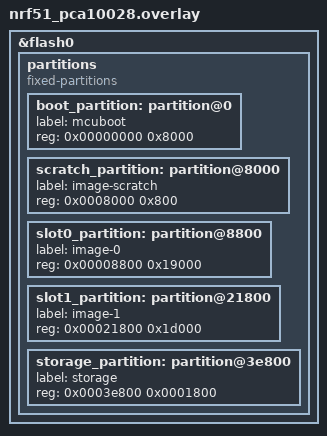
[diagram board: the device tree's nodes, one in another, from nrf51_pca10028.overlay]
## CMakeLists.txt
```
# SPDX-License-Identifier: Apache-2.0

cmake_minimum_required(VERSION 3.13.1)
include($ENV{ZEPHYR_BASE}/cmake/app/boilerplate.cmake NO_POLICY_SCOPE)
project(test_zepboot)

FILE(GLOB app_sources ../zepboot/src/*.c src/*.c)

target_sources(app PRIVATE ${app_sources})
```

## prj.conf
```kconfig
CONFIG_ZTEST=y
CONFIG_ZTEST_STACKSIZE=8120
CONFIG_MAIN_STACK_SIZE=4096
CONFIG_FLASH=y
CONFIG_FLASH_PAGE_LAYOUT=y
CONFIG_FLASH_MAP=y

CONFIG_TINYCRYPT=y
CONFIG_TINYCRYPT_SHA256=y
CONFIG_TINYCRYPT_ECC_DH=y
CONFIG_TINYCRYPT_ECC_DSA=y
CONFIG_TINYCRYPT_AES=y
CONFIG_TINYCRYPT_AES_CTR=y

CONFIG_LOG=y
CONFIG_LOG_IMMEDIATE=y
```

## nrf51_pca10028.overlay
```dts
/*
 * Copyright (c) 2019 Laczen
 *
 * SPDX-License-Identifier: Apache-2.0
 */

/delete-node/ &storage_partition;
/delete-node/ &slot0_partition;
/delete-node/ &slot1_partition;
/delete-node/ &scratch_partition;
/delete-node/ &boot_partition;

&flash0 {
	/*
	 * For more information, see:
	 * http://docs.zephyrproject.org/latest/guides/dts/index.html#flash-partitions
	 */
	partitions {
		compatible = "fixed-partitions";
		#address-cells = <1>;
		#size-cells = <1>;

		boot_partition: partition@0 {
			label = "mcuboot";
			reg = <0x00000000 0x8000>;
		};
		scratch_partition: partition@8000 {
			label = "image-scratch";
			reg = <0x0008000 0x800>;
		};
		slot0_partition: partition@8800 {
			label = "image-0";
			reg = <0x00008800 0x19000>;
		};
		slot1_partition: partition@21800 {
			label = "image-1";
			reg = <0x00021800 0x1d000>;
		};

		storage_partition: partition@3e800 {
			label = "storage";
			reg = <0x0003e800 0x0001800>;
		};
	};
};
```

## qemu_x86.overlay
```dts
/*
 * Copyright (c) 2019 Laczen
 *
 * SPDX-License-Identifier: Apache-2.0
 */

/delete-node/ &storage_partition;
/delete-node/ &slot0_partition;
/delete-node/ &slot1_partition;

&flash_sim0 {
	/*
	 * For more information, see:
	 * http://docs.zephyrproject.org/latest/guides/dts/index.html#flash-partitions
	 */
	partitions {
		compatible = "fixed-partitions";
		#address-cells = <1>;
		#size-cells = <1>;

		storage_partition: partition@1000 {
			label = "storage";
			reg = <0x00001000 0x00010000>;
		};

		slot0_partition: partition@11000 {
			label = "image-0";
			reg = <0x00011000 0x00010000>;
		};
		slot1_partition: partition@21000 {
			label = "image-1";
			reg = <0x00021000 0x00010000>;
		};
		scratch_partition: partition@31000 {
			label = "image-scratch";
			reg = <0x00031000 0x000800>;
		};
	};
};
```

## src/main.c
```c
/*
 * Copyright (c) 2017 Nordic Semiconductor ASA
 * Copyright (c) 2015 Runtime Inc
 *
 * SPDX-License-Identifier: Apache-2.0
 */

#include <logging/log.h>
LOG_MODULE_REGISTER(main);

extern void test_zb_flash(void);
extern void test_zb_ec256(void);
extern void test_zb_tlv(void);
extern void test_zb_aes(void);
extern void test_zb_image(void);
extern void test_zb_move(void);

void test_main(void)
{
	test_zb_flash();
	test_zb_ec256();
	test_zb_tlv();
	test_zb_aes();
	test_zb_image();
	test_zb_move();
}
```

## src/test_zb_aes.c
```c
/*
 * Copyright (c) 2017 Nordic Semiconductor ASA
 * Copyright (c) 2015 Runtime Inc
 *
 * SPDX-License-Identifier: Apache-2.0
 */

#include <ztest.h>
#include <errno.h>
#include <flash.h>
#include "../../zepboot/include/zb_flash.h"
#include "../../zepboot/include/zb_tlv.h"
#include "../../zepboot/include/zb_image.h"
#include "../../zepboot/include/zb_aes.h"
#include "../../zepboot/include/zb_move.h"


#include <logging/log.h>
LOG_MODULE_REGISTER(test_zb_aes);

extern u8_t test_msg[];
extern u8_t ec256_boot_pri_key[];
u8_t enc_test_msg[HASH_BYTES];
u8_t dec_test_msg[HASH_BYTES];

/**
 * @brief Test the aes enc routine
 */
void test_zb_aes_enc(void)
{
	int err;

	u8_t ctr[AES_BLOCK_SIZE]={0};

	memcpy(enc_test_msg, test_msg, HASH_BYTES);
	err = zb_aes_ctr_mode(enc_test_msg, HASH_BYTES, ctr,
			      ec256_boot_pri_key);
	zassert_true(err == 0,  "AES CTR returned [err %d]", err);
	err = ctr[15] - HASH_BYTES/AES_BLOCK_SIZE;
	zassert_true(err == 0,  "AES CTR wrong CTR value");
	err = memcmp(enc_test_msg, test_msg, HASH_BYTES);
	zassert_false(err == 0,  "AES wrong encrypt data");

}
void test_zb_aes_dec(void)
{
	int err;

	u8_t ctr[AES_BLOCK_SIZE]={0};

	memcpy(dec_test_msg, enc_test_msg, HASH_BYTES);
	err = zb_aes_ctr_mode(dec_test_msg, HASH_BYTES, ctr,
			      ec256_boot_pri_key);
	zassert_true(err == 0,  "AES CTR returned [err %d]", err);
	err = ctr[15] - HASH_BYTES/AES_BLOCK_SIZE;
	zassert_true(err == 0,  "AES CTR wrong CTR value");
	err = memcmp(dec_test_msg, test_msg, HASH_BYTES);
	zassert_true(err == 0,  "AES wrong decrypt data");

}

void test_zb_aes(void)
{
	ztest_test_suite(test_zb_aes,
			 ztest_unit_test(test_zb_aes_enc),
			 ztest_unit_test(test_zb_aes_dec)
			);

	ztest_run_test_suite(test_zb_aes);
}
```

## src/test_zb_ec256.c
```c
/*
 * Copyright (c) 2017 Nordic Semiconductor ASA
 * Copyright (c) 2015 Runtime Inc
 *
 * SPDX-License-Identifier: Apache-2.0
 */

#include <ztest.h>
#include <errno.h>
#include <flash.h>
#include "../../zepboot/include/zb_flash.h"
#include "../../zepboot/include/zb_ec256.h"

#include <logging/log.h>
LOG_MODULE_REGISTER(test_zb_ec256);

extern u8_t test_msg[];
extern u8_t test_msg_hash[];
extern u32_t test_msg_crc32;

/**
 * @brief Test hash calculation for data in flash
 */
void test_zb_hash_flash(void)
{
	int err, cnt;
	struct zb_slt_area area;
	u8_t hash[HASH_BYTES];

	cnt = zb_slt_area_cnt();
	zassert_false(cnt == 0,  "Unable to get slotarea count: [cnt %d]", cnt);

	err = zb_slt_area_get(&area, 0);
	zassert_true(err == 0,  "Unable to get slotarea info: [err %d]", err);

	err = zb_flash_erase(area.slt0_fldev, area.slt0_offset, area.slt0_size);
	zassert_true(err == 0,  "Unable to erase image 0 area: [err %d]", err);

	err = zb_flash_write(area.slt0_fldev, area.slt0_offset, test_msg,
			     HASH_BYTES);
	zassert_true(err == 0,  "Unable to write test message: [err %d]", err);

	err = zb_hash_flash(hash, area.slt0_fldev, area.slt0_offset,
			    HASH_BYTES);
	zassert_true(err == 0, "Hash calculation failed: [err %d]", err);

	err = memcmp(hash, test_msg_hash, HASH_BYTES);
	zassert_true(err == 0, "Hash differs");
}

extern u8_t test_signature[];

/**
 * @brief Test signature verification
 */
void test_zb_sign_verify(void)
{
	int err;
	u8_t tmp;

	err = zb_sign_verify(test_msg_hash, test_signature);
	zassert_true(err == 0, "Signature validation failed: [err %d]", err);

	/* modify the key */
	tmp = test_msg_hash[0];
	test_msg_hash[0] >>=1;
	err = zb_sign_verify(test_msg_hash, test_signature);
	zassert_false(err == 0, "Invalid hash generates valid signature");

	/* reset the key */
	test_msg_hash[0] = tmp;

}

extern u8_t test_enc_pub_key[];
extern u8_t test_enc_key[];

/**
 * @brief Test the generation of an encryption key from public key
 */
void test_zb_get_encr_key(void)
{
	int err;
	u8_t enc_key[16], tmp;

	err = zb_get_encr_key(enc_key, test_enc_pub_key, 16);
	zassert_true(err == 0,  "Failed to get encryption key: [err %d]", err);
	err = memcmp(enc_key, test_enc_key, 16);
	zassert_true(err == 0,  "Encryption keys differ: [err %d]", err);

	/* modify the key */
	tmp = test_enc_pub_key[0];
	test_enc_pub_key[0] >>= 1;
	err = zb_get_encr_key(enc_key, test_enc_pub_key, 16);
	zassert_false(err == 0,  "Invalid pubkey generates encryption key");

	/* reset the key */
	test_enc_pub_key[0] = tmp;

}

/**
 * @brief Test the generation of an encryption key from public key
 */
void test_zb_crc32(void)
{
	int err, cnt;
	struct zb_slt_area area;
	u32_t crc32;

	cnt = zb_slt_area_cnt();
	zassert_false(cnt == 0,  "Unable to get slotarea count: [cnt %d]", cnt);

	err = zb_slt_area_get(&area, 0);
	zassert_true(err == 0,  "Unable to get slotarea info: [err %d]", err);

	err = zb_flash_erase(area.slt0_fldev, area.slt0_offset, area.slt0_size);
	zassert_true(err == 0,  "Unable to erase image 0 area: [err %d]", err);

	err = zb_flash_write(area.slt0_fldev, area.slt0_offset, test_msg,
			     HASH_BYTES);
	zassert_true(err == 0,  "Unable to write test message: [err %d]", err);

	err = zb_crc32_flash(&crc32, area.slt0_fldev, area.slt0_offset,
			    HASH_BYTES);
	zassert_true(err == 0, "CRC32 calculation failed: [err %d]", err);

	err = crc32 - test_msg_crc32;
	zassert_true(err == 0, "CRC32 differs");

}

void test_zb_ec256(void)
{
	ztest_test_suite(test_zb_ec256,
			 ztest_unit_test(test_zb_hash_flash),
			 ztest_unit_test(test_zb_sign_verify),
			 ztest_unit_test(test_zb_get_encr_key),
			 ztest_unit_test(test_zb_crc32)
	);

	ztest_run_test_suite(test_zb_ec256);
}
```

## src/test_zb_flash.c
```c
/*
 * Copyright (c) 2017 Nordic Semiconductor ASA
 * Copyright (c) 2015 Runtime Inc
 *
 * SPDX-License-Identifier: Apache-2.0
 */

#include <ztest.h>
#include <errno.h>
#include <flash.h>
#include "../../zepboot/include/zb_flash.h"

#include <logging/log.h>
LOG_MODULE_REGISTER(test_zb_flash);

/**
 * @brief Test zb_get_area()
 */
void test_zb_get_area(void)
{
	int err, cnt;
	struct zb_slt_area area;

	cnt = zb_slt_area_cnt();
	zassert_false(cnt == 0,  "Unable to get slotarea count: [cnt %d]", cnt);

	while (cnt > 0) {
		err = zb_slt_area_get(&area, cnt - 1);
		zassert_true(err == 0,  "Unable to get slotarea info: [err %d]",
			     err);
		cnt--;
	}
}

/**
 * @brief Test read and write of zb commands
 */
void test_zb_cmd(void)
{
	int err, cnt;
	struct zb_slt_area area;
	struct zb_cmd cmd, cmd_rd;

	cnt = zb_slt_area_cnt();
	zassert_false(cnt == 0,  "Unable to get slotarea count: [cnt %d]", cnt);

	err = zb_slt_area_get(&area, 0);
	zassert_true(err == 0,  "Unable to get slotarea info: [err %d]", err);

	err = zb_erase_swpstat(&area);
	zassert_true(err == 0,  "Unable to erase stat area: [err %d]", err);

	err = zb_cmd_read_swpstat(&area, &cmd_rd);
	zassert_true(err = -ENOENT, "Found cmd entry in empty flash area");

	cmd.cmd1 = 0x0;
	cmd.cmd2 = 0x0;
	cmd.cmd3 = 0x0;

	err = zb_cmd_write_swpstat(&area, &cmd);
	zassert_true(err == 0, "Failed to write command");

	err = zb_cmd_read_swpstat(&area, &cmd_rd);
	zassert_true(((cmd.cmd1 == cmd_rd.cmd1) && (cmd.cmd2 == cmd_rd.cmd2) &&
		     (cmd.cmd3 == cmd_rd.cmd3)),
		      "Found different cmd entry in flash area");

	/* write commands until stat area is full */
	while (err == 0) {
		cmd.cmd3++;
		err = zb_cmd_write_swpstat(&area, &cmd);
		if (cmd.cmd3 > 1024) {
			break;
		}
	}
	zassert_true(err == -ENOSPC, "To many cmd writes possible");
}

/**
 * @brief Test read and write of zb image parameters
 */
void test_zb_prm(void)
{
	int err, cnt;
	struct zb_slt_area area;
	struct zb_prm prm, prm_rd;

	cnt = zb_slt_area_cnt();
	zassert_false(cnt == 0,  "Unable to get slotarea count: [cnt %d]", cnt);

	err = zb_slt_area_get(&area, 0);
	zassert_true(err == 0,  "Unable to get slotarea info: [err %d]", err);

	err = zb_erase_slt0end(&area);
	zassert_true(err == 0,  "Unable to erase stat area: [err %d]", err);

	prm.slt0_crc32 = 0x0;
	prm.slt0_ver = 0x0;
	prm.pri_ld_address = 0x0;
	prm.slt1_crc32 = 0x0;
	prm.slt1_ver = 0x0;
	prm.sec_ld_address = 0x0;

	err = zb_prm_write(&area, &prm);
	zassert_true(err == 0,  "Unable to write prm: [err %d]", err);

	err = zb_prm_read(&area, &prm_rd);
	zassert_true(err == 0,  "Unable to read prm: [err %d]", err);

	err = memcmp(&prm, &prm_rd, sizeof(struct zb_prm));
	zassert_true(err == 0, "Rd/wr prm differs: [err %d]", err);

}

void test_zb_flash(void)
{
	ztest_test_suite(test_zb_flash,
			 ztest_unit_test(test_zb_get_area),
			 ztest_unit_test(test_zb_cmd),
			 ztest_unit_test(test_zb_prm)
			);

	ztest_run_test_suite(test_zb_flash);

}
```

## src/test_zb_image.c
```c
/*
 * Copyright (c) 2017 Nordic Semiconductor ASA
 * Copyright (c) 2015 Runtime Inc
 *
 * SPDX-License-Identifier: Apache-2.0
 */

#include <ztest.h>
#include <errno.h>
#include <flash.h>
#include "../../zepboot/include/zb_flash.h"
#include "../../zepboot/include/zb_tlv.h"
#include "../../zepboot/include/zb_image.h"

#include <logging/log.h>
LOG_MODULE_REGISTER(test_zb_image);

extern const unsigned char test_image_slt0[1536];
extern const unsigned char test_image_slt1[1536];
extern const unsigned char test_image_slt0_enc[1536];
extern const unsigned char test_image_slt1_enc[1536];

#define HDR_SIZE 512

/**
 * @brief Test the opening of a image in slot 0
 * test_image_slt0[] has been generated for load_address 0x11200
 * test_image_slt1[] has been generated for load_address 0x21200
 */
void test_zb_get_image_info_slt0(void)
{
	int err, cnt;
	struct zb_slt_area area;
	zb_img_info info;

	cnt = zb_slt_area_cnt();
	zassert_false(cnt == 0,  "Unable to get slotarea count: [cnt %d]", cnt);

	err = zb_slt_area_get(&area, 0);
	zassert_true(err == 0,  "Unable to get slotarea info: [err %d]", err);

	err = zb_flash_erase(area.slt0_fldev, area.slt0_offset, area.slt0_size);
	zassert_true(err == 0,  "Unable to erase image 0 area: [err %d]", err);

	err = zb_flash_write(area.slt0_fldev, area.slt0_offset, test_image_slt0,
			     sizeof(test_image_slt0));
	zassert_true(err == 0,  "Unable to write the image: [err %d]", err);

	/* without signature verification */
	zb_img_get_info_nsc(&info, &area, false, 0, true);
	zassert_true(info.is_valid,  "Error loading image info: [err %d]", err);
	err = info.hdr_start - area.slt0_offset;
	zassert_true(err == 0,  "Wrong hdr start [%x] [%x]", info.start,
		     area.slt0_offset);
	err = info.start - area.slt0_offset - HDR_SIZE;
	zassert_true(err == 0,  "Wrong img start");
	err = info.load_address - (area.slt0_offset + HDR_SIZE);
	zassert_true(err == 0,  "Wrong load address");

	/* with signature verification */
	zb_img_get_info_wsc(&info, &area, false, 0, true);
	zassert_true(info.is_valid,  "Error loading image info: [err %d]", err);
	err = info.hdr_start - area.slt0_offset;
	zassert_true(err == 0,  "Wrong hdr start [%x] [%x]", info.start,
		     area.slt0_offset);
	err = info.start - area.slt0_offset - HDR_SIZE;
	zassert_true(err == 0,  "Wrong img start");
	err = info.load_address - (area.slt0_offset + HDR_SIZE);
	zassert_true(err == 0,  "Wrong load address");

}

/**
 * @brief Test the opening of a encrypted image in slot 0
 * test_image_slt0_enc[] has been generated for load_address 0x11200
 * test_image_slt1_enc[] has been generated for load_address 0x21200
 */
void test_zb_get_image_info_slt0_enc(void)
{
	int err, cnt;
	struct zb_slt_area area;
	zb_img_info info;

	cnt = zb_slt_area_cnt();
	zassert_false(cnt == 0,  "Unable to get slotarea count: [cnt %d]", cnt);

	err = zb_slt_area_get(&area, 0);
	zassert_true(err == 0,  "Unable to get slotarea info: [err %d]", err);

	err = zb_flash_erase(area.slt0_fldev, area.slt0_offset, area.slt0_size);
	zassert_true(err == 0,  "Unable to erase image 0 area: [err %d]", err);

	err = zb_flash_write(area.slt0_fldev, area.slt0_offset,
			     test_image_slt0_enc, sizeof(test_image_slt0_enc));
	zassert_true(err == 0,  "Unable to write the image: [err %d]", err);

	/* without signature verification */
	zb_img_get_info_nsc(&info, &area, false, 0, true);
	zassert_true(info.is_valid,  "Error loading image info: [err %d]", err);
	err = info.hdr_start - area.slt0_offset;
	zassert_true(err == 0,  "Wrong hdr start [%x] [%x]", info.start,
		     area.slt0_offset);
	err = info.start - area.slt0_offset - HDR_SIZE;
	zassert_true(err == 0,  "Wrong img start");
	err = info.enc_start - area.slt0_offset - HDR_SIZE;
	zassert_true(err == 0,  "Wrong encryption start");
	err = info.load_address - (area.slt0_offset + HDR_SIZE);
	zassert_true(err == 0,  "Wrong load address");

	/* with signature verification */
	zb_img_get_info_wsc(&info, &area, false, 0, true);
	zassert_true(info.is_valid,  "Error loading image info: [err %d]", err);
	err = info.hdr_start - area.slt0_offset;
	zassert_true(err == 0,  "Wrong hdr start [%x] [%x]", info.start,
		     area.slt0_offset);
	err = info.start - area.slt0_offset - HDR_SIZE;
	zassert_true(err == 0,  "Wrong img start");
	err = info.enc_start - area.slt0_offset - HDR_SIZE;
	zassert_true(err == 0,  "Wrong encryption start");
	err = info.load_address - (area.slt0_offset + HDR_SIZE);
	zassert_true(err == 0,  "Wrong load address");

}

/**
 * @brief Test the opening of a image in slot 1
 * test_image_slt0[] has been generated for load_address 0x11200
 * test_image_slt1[] has been generated for load_address 0x21200
 */
void test_zb_get_image_info_slt1(void)
{
	int err, cnt;
	struct zb_slt_area area;
	zb_img_info info;

	cnt = zb_slt_area_cnt();
	zassert_false(cnt == 0,  "Unable to get slotarea count: [cnt %d]", cnt);

	err = zb_slt_area_get(&area, 0);
	zassert_true(err == 0,  "Unable to get slotarea info: [err %d]", err);

	err = zb_flash_erase(area.slt1_fldev, area.slt1_offset, area.slt1_size);
	zassert_true(err == 0,  "Unable to erase image 0 area: [err %d]", err);

	err = zb_flash_write(area.slt1_fldev, area.slt1_offset, test_image_slt0,
			     sizeof(test_image_slt0));
	zassert_true(err == 0,  "Unable to write the image: [err %d]", err);

	/* without signature verification */
	zb_img_get_info_nsc(&info, &area, true, 0, true);
	zassert_true(info.is_valid,  "Error loading image info: [err %d]", err);
	err = info.hdr_start - area.slt1_offset;
	zassert_true(err == 0,  "Wrong hdr start [%x] [%x]", info.start,
		     area.slt1_offset);
	err = info.start - area.slt1_offset - HDR_SIZE;
	zassert_true(err == 0,  "Wrong img start");
	err = info.load_address - (area.slt0_offset + HDR_SIZE);
	zassert_true(err == 0,  "Wrong load address");

	/* with signature verification */
	zb_img_get_info_wsc(&info, &area, true, 0, true);
	zassert_true(info.is_valid,  "Error loading image info: [err %d]", err);
	err = info.hdr_start - area.slt1_offset;
	zassert_true(err == 0,  "Wrong hdr start [%x] [%x]", info.start,
		     area.slt1_offset);
	err = info.start - area.slt1_offset - HDR_SIZE;
	zassert_true(err == 0,  "Wrong img start");
	err = info.load_address - (area.slt0_offset + HDR_SIZE);
	zassert_true(err == 0,  "Wrong load address");

}

/**
 * @brief Test the opening of a encrypted image in slot 1
 * test_image_slt0[] has been generated for load_address 0x11200
 * test_image_slt1[] has been generated for load_address 0x21200
 */
void test_zb_get_image_info_slt1_enc(void)
{
	int err, cnt;
	struct zb_slt_area area;
	zb_img_info info;

	cnt = zb_slt_area_cnt();
	zassert_false(cnt == 0,  "Unable to get slotarea count: [cnt %d]", cnt);

	err = zb_slt_area_get(&area, 0);
	zassert_true(err == 0,  "Unable to get slotarea info: [err %d]", err);

	err = zb_flash_erase(area.slt1_fldev, area.slt1_offset, area.slt1_size);
	zassert_true(err == 0,  "Unable to erase image 0 area: [err %d]", err);

	err = zb_flash_write(area.slt1_fldev, area.slt1_offset,
			     test_image_slt0_enc, sizeof(test_image_slt0_enc));
	zassert_true(err == 0,  "Unable to write the image: [err %d]", err);

	/* without signature verification */
	zb_img_get_info_nsc(&info, &area, true, 0, true);
	zassert_true(info.is_valid,  "Error loading image info: [err %d]", err);
	err = info.hdr_start - area.slt1_offset;
	zassert_true(err == 0,  "Wrong hdr start [%x] [%x]", info.start,
		     area.slt1_offset);
	err = info.start - area.slt1_offset - HDR_SIZE;
	zassert_true(err == 0,  "Wrong img start");
	err = info.enc_start - area.slt1_offset - HDR_SIZE;
	zassert_true(err == 0,  "Wrong encryption start");
	err = info.load_address - (area.slt0_offset + HDR_SIZE);
	zassert_true(err == 0,  "Wrong load address");

	/* with signature verification */
	zb_img_get_info_wsc(&info, &area, true, 0, true);
	zassert_true(info.is_valid,  "Error loading image info: [err %d]", err);
	err = info.hdr_start - area.slt1_offset;
	zassert_true(err == 0,  "Wrong hdr start [%x] [%x]", info.start,
		     area.slt1_offset);
	err = info.start - area.slt1_offset - HDR_SIZE;
	zassert_true(err == 0,  "Wrong img start");
	err = info.enc_start - area.slt1_offset - HDR_SIZE;
	zassert_true(err == 0,  "Wrong encryption start");
	err = info.load_address - (area.slt0_offset + HDR_SIZE);
	zassert_true(err == 0,  "Wrong load address");

}

/**
 * @brief Test the image check (this is carried out in slt1)
 * test_image_slt0[] has been generated for load_address 0x11200
 * test_image_slt1[] has been generated for load_address 0x21200
 */
void test_zb_check_image(void)
{
	int err, cnt;
	struct zb_slt_area area;
	struct zb_prm prm;
	u8_t slt;

	cnt = zb_slt_area_cnt();
	zassert_false(cnt == 0,  "Unable to get slotarea count: [cnt %d]", cnt);

	err = zb_slt_area_get(&area, 0);
	zassert_true(err == 0,  "Unable to get slotarea info: [err %d]", err);

	err = zb_flash_erase(area.slt1_fldev, area.slt1_offset, area.slt1_size);
	zassert_true(err == 0,  "Unable to erase image 1 area: [err %d]", err);

	err = zb_flash_write(area.slt1_fldev, area.slt1_offset, test_image_slt0,
			     sizeof(test_image_slt0));
	zassert_true(err == 0,  "Unable to write the image: [err %d]", err);

	err = zb_img_check(&area, &slt);
	zassert_true(err == 0,  "Image check failed");
	zassert_true(slt == 0,  "Wrong slot");

	err = zb_flash_erase(area.slt1_fldev, area.slt1_offset, area.slt1_size);
	zassert_true(err == 0,  "Unable to erase image 1 area: [err %d]", err);

	err = zb_flash_write(area.slt1_fldev, area.slt1_offset, test_image_slt1,
			     sizeof(test_image_slt1));
	zassert_true(err == 0,  "Unable to write the image: [err %d]", err);

	err = zb_img_check(&area, &slt);
	zassert_true(err == 0,  "Image check failed");
	zassert_true(slt == 1,  "Wrong slot");

	prm.pri_ld_address = area.slt1_offset;
	prm.slt0_ver = 1;
	err = zb_prm_write(&area, &prm);
	zassert_true(err == 0,  "Unable to write prm area: [err %d]", err);

	err = zb_img_check(&area, &slt);
	zassert_false(err == 0,  "Image check failed");
}

void test_zb_image(void)
{
	ztest_test_suite(test_zb_image,
			 ztest_unit_test(test_zb_get_image_info_slt0),
			 ztest_unit_test(test_zb_get_image_info_slt0_enc),
			 ztest_unit_test(test_zb_get_image_info_slt1),
			 ztest_unit_test(test_zb_get_image_info_slt1_enc),
			 ztest_unit_test(test_zb_check_image)
			);

	ztest_run_test_suite(test_zb_image);
}
```

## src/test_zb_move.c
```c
/*
 * Copyright (c) 2017 Nordic Semiconductor ASA
 * Copyright (c) 2015 Runtime Inc
 *
 * SPDX-License-Identifier: Apache-2.0
 */

#include <ztest.h>
#include <errno.h>
#include <flash.h>
#include "../../zepboot/include/zb_flash.h"
#include "../../zepboot/include/zb_tlv.h"
#include "../../zepboot/include/zb_image.h"
#include "../../zepboot/include/zb_move.h"


#include <logging/log.h>
LOG_MODULE_REGISTER(test_zb_move);

extern const unsigned char test_image_slt0[1536];
extern const unsigned char test_image_slt1[1536];
extern const unsigned char test_image_slt0_enc[1536];
extern const unsigned char test_image_slt1_enc[1536];

#define HDR_SIZE 512
/**
 * @brief Test the classic unencrypted move
 */
void test_zb_image_classic_move_clr(void)
{
	int err, cnt;
	struct zb_slt_area area;
	struct zb_cmd cmd;
	u8_t imgheader[HDR_SIZE];
	u8_t img[1536-HDR_SIZE];

	cnt = zb_slt_area_cnt();
	zassert_false(cnt == 0, "Unable to get slotarea count: [cnt %d]", cnt);
	err = zb_slt_area_get(&area, 0);
	zassert_true(err == 0, "Unable to get slotarea info: [err %d]", err);

	err = zb_flash_erase(area.slt1_fldev, area.slt1_offset, area.slt1_size);
	zassert_true(err == 0, "Unable to erase image 1 area: [err %d]", err);

	err = zb_flash_write(area.slt1_fldev, area.slt1_offset, test_image_slt0,
			     sizeof(test_image_slt0));
	zassert_true(err == 0, "Unable to write image data: [err %d]", err);

	err = zb_flash_erase(area.swpstat_fldev, area.swpstat_offset,
			     area.swpstat_size);
	zassert_true(err == 0, "Unable to erase swpstat area: [err %d]", err);
	cmd.cmd1 = 0;
	cmd.cmd2 = CMD2_SWP_START;
	cmd.cmd3 = 0x0;

	err = zb_cmd_write_swpstat(&area, &cmd);
	zassert_true(err == 0, "Failed to write command");

	err = zb_img_swap(&area);

	err = zb_flash_read(area.slt0_fldev, area.slt0_offset,
			    imgheader, HDR_SIZE);
	zassert_true(err == 0, "Unable to read moved header");
	err = memcmp(imgheader, test_image_slt0, HDR_SIZE);
	zassert_true(err == 0, "Difference detected in moved header");

	err = zb_flash_read(area.slt0_fldev, area.slt0_offset + HDR_SIZE,
			    img, 1536 - HDR_SIZE);
	zassert_true(err == 0, "Unable to read moved image");
	err = memcmp(img, &test_image_slt0[HDR_SIZE], 1536 - HDR_SIZE);
	zassert_true(err == 0, "Difference detected in image");
}

/**
 * @brief Test the classic encrypted move
 */
void test_zb_image_classic_move_enc(void)
{
	int err, cnt;
	struct zb_slt_area area;
	struct zb_cmd cmd;
	u8_t imgheader[HDR_SIZE];
	u8_t img[1536-HDR_SIZE];

	cnt = zb_slt_area_cnt();
	zassert_false(cnt == 0, "Unable to get slotarea count: [cnt %d]", cnt);
	err = zb_slt_area_get(&area, 0);
	zassert_true(err == 0, "Unable to get slotarea info: [err %d]", err);

	err = zb_flash_erase(area.slt1_fldev, area.slt1_offset, area.slt1_size);
	zassert_true(err == 0, "Unable to erase image 1 area: [err %d]", err);

	err = zb_flash_write(area.slt1_fldev, area.slt1_offset,
			     test_image_slt0_enc, sizeof(test_image_slt0_enc));
	zassert_true(err == 0, "Unable to write image data: [err %d]", err);

	err = zb_flash_erase(area.swpstat_fldev, area.swpstat_offset,
			     area.swpstat_size);
	zassert_true(err == 0, "Unable to erase swpstat area: [err %d]", err);
	cmd.cmd1 = 0;
	cmd.cmd2 = CMD2_SWP_START;
	cmd.cmd3 = 0x0;

	err = zb_cmd_write_swpstat(&area, &cmd);
	zassert_true(err == 0, "Failed to write command");

	err = zb_img_swap(&area);

	err = zb_flash_read(area.slt0_fldev, area.slt0_offset,
			    imgheader, HDR_SIZE);
	zassert_true(err == 0, "Unable to read moved header");
	err = memcmp(imgheader, test_image_slt0_enc, HDR_SIZE);
	zassert_true(err == 0, "Difference detected in moved header");

	err = zb_flash_read(area.slt0_fldev, area.slt0_offset + HDR_SIZE,
			    img, 1536 - HDR_SIZE);
	zassert_true(err == 0, "Unable to read moved image");
	/* test_image_slt0 contains unencrypted test_image_slt0_enc */
	err = memcmp(img, &test_image_slt0[HDR_SIZE], 1536 - HDR_SIZE);
	zassert_true(err == 0, "Difference detected in image");
}

/**
 * @brief Test the inplace unencrypted move
 */
void test_zb_image_inplace_move_clr(void)
{
	int err, cnt;
	struct zb_slt_area area;
	struct zb_cmd cmd;
	u8_t imgheader[HDR_SIZE];
	u8_t img[1536-HDR_SIZE];

	cnt = zb_slt_area_cnt();
	zassert_false(cnt == 0, "Unable to get slotarea count: [cnt %d]", cnt);
	err = zb_slt_area_get(&area, 0);
	zassert_true(err == 0, "Unable to get slotarea info: [err %d]", err);

	err = zb_flash_erase(area.slt1_fldev, area.slt1_offset, area.slt1_size);
	zassert_true(err == 0, "Unable to erase image 1 area: [err %d]", err);

	err = zb_flash_write(area.slt1_fldev, area.slt1_offset, test_image_slt1,
			     sizeof(test_image_slt1));
	zassert_true(err == 0, "Unable to write image data: [err %d]", err);

	err = zb_flash_erase(area.swpstat_fldev, area.swpstat_offset,
			     area.swpstat_size);
	zassert_true(err == 0, "Unable to erase swpstat area: [err %d]", err);
	cmd.cmd1 = 0;
	cmd.cmd2 = CMD2_SWP_START | CMD2_MASK_INPLACE;
	cmd.cmd3 = 0x0;

	err = zb_cmd_write_swpstat(&area, &cmd);
	zassert_true(err == 0, "Failed to write command");

	err = zb_img_swap(&area);

	err = zb_flash_read(area.slt1_fldev, area.slt1_offset,
			    imgheader, HDR_SIZE);
	zassert_true(err == 0, "Unable to read moved header");
	err = memcmp(imgheader, test_image_slt1, HDR_SIZE);
	zassert_true(err == 0, "Difference detected in moved header");

	err = zb_flash_read(area.slt1_fldev, area.slt1_offset + HDR_SIZE,
			    img, 1536 - HDR_SIZE);
	zassert_true(err == 0, "Unable to read moved image");
	err = memcmp(img, &test_image_slt1[HDR_SIZE], 1536 - HDR_SIZE);
	zassert_true(err == 0, "Difference detected in image");
}

/**
 * @brief Test the in place encrypted move
 */
void test_zb_image_inplace_move_enc(void)
{
	int err, cnt;
	struct zb_slt_area area;
	struct zb_cmd cmd;
	u8_t imgheader[HDR_SIZE];
	u8_t img[1536-HDR_SIZE];

	cnt = zb_slt_area_cnt();
	zassert_false(cnt == 0, "Unable to get slotarea count: [cnt %d]", cnt);
	err = zb_slt_area_get(&area, 0);
	zassert_true(err == 0, "Unable to get slotarea info: [err %d]", err);

	err = zb_flash_erase(area.slt1_fldev, area.slt1_offset, area.slt1_size);
	zassert_true(err == 0, "Unable to erase image 1 area: [err %d]", err);

	err = zb_flash_write(area.slt1_fldev, area.slt1_offset,
			     test_image_slt1_enc, sizeof(test_image_slt1_enc));
	zassert_true(err == 0, "Unable to write image data: [err %d]", err);

	err = zb_flash_erase(area.swpstat_fldev, area.swpstat_offset,
			     area.swpstat_size);
	zassert_true(err == 0, "Unable to erase swpstat area: [err %d]", err);
	cmd.cmd1 = 0;
	cmd.cmd2 = CMD2_SWP_START | CMD2_MASK_INPLACE;
	cmd.cmd3 = 0x0;

	err = zb_cmd_write_swpstat(&area, &cmd);
	zassert_true(err == 0, "Failed to write command");

	err = zb_img_swap(&area);

	err = zb_flash_read(area.slt1_fldev, area.slt1_offset,
			    imgheader, HDR_SIZE);
	zassert_true(err == 0, "Unable to read moved header");
	err = memcmp(imgheader, test_image_slt1_enc, HDR_SIZE);
	zassert_true(err == 0, "Difference detected in moved header");

	err = zb_flash_read(area.slt1_fldev, area.slt1_offset + HDR_SIZE,
			    img, 1536 - HDR_SIZE);
	zassert_true(err == 0, "Unable to read moved image");
	err = memcmp(img, &test_image_slt1[HDR_SIZE], 1536 - HDR_SIZE);
	zassert_true(err == 0, "Difference detected in image");

}

void test_zb_move(void)
{
	ztest_test_suite(test_zb_move,
			 ztest_unit_test(test_zb_image_classic_move_clr),
			 ztest_unit_test(test_zb_image_classic_move_enc),
			 ztest_unit_test(test_zb_image_inplace_move_clr),
			 ztest_unit_test(test_zb_image_inplace_move_enc)
			);

	ztest_run_test_suite(test_zb_move);
}
```

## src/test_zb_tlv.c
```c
/*
 * Copyright (c) 2017 Nordic Semiconductor ASA
 * Copyright (c) 2015 Runtime Inc
 *
 * SPDX-License-Identifier: Apache-2.0
 */

#include <ztest.h>
#include <errno.h>
#include <flash.h>
#include "../../zepboot/include/zb_flash.h"
#include "../../zepboot/include/zb_tlv.h"

#include <logging/log.h>
LOG_MODULE_REGISTER(test_zb_tlv);

extern u8_t test_msg[];
extern u8_t test_signature[];

#define HAYSTACK_BYTES 16
u8_t test_haystack[HAYSTACK_BYTES] = {
	1,2,1,2, 	/* type = 1, length = 2, value = 1 2 */
	2,3,3,4,5, 	/* type = 2, length = 3, value = 3 4 5 */
	3,1,6,		/* type = 3, length = 1, value = 6 */
	4,2,7,8		/* type = 4, length = 1, value = 7 8 */

};

/**
 * @brief Test tlv_step method to step through a haystack in ram
 */
void test_zb_tlv_step(void)
{
	int err;
	tlv_entry entry;
	off_t offset;

	offset = 0;
	entry.type = 0;
	while ((entry.type != 1) && (offset < HAYSTACK_BYTES)) {
		zb_step_tlv(test_haystack, &offset, &entry);
	}
	zassert_true(entry.type == 1, "Entry type 1 not found");
	err = memcmp(&test_haystack[2], entry.value, entry.length);
	zassert_true(err == 0, "Entry type 1 wrong value");

	offset = 0;
	entry.type = 0;
	while ((entry.type != 2) && (offset < HAYSTACK_BYTES)) {
		zb_step_tlv(test_haystack, &offset, &entry);
	}
	zassert_true(entry.type == 2, "Entry type 2 not found");
	err = memcmp(&test_haystack[6], entry.value, entry.length);
	zassert_true(err == 0, "Entry type 2 wrong value");

	offset = 0;
	entry.type = 0;
	while ((entry.type != 3) && (offset < HAYSTACK_BYTES)) {
		zb_step_tlv(test_haystack, &offset, &entry);
	}
	zassert_true(entry.type == 3, "Entry type 3 not found");
	err = memcmp(&test_haystack[11], entry.value, entry.length);
	zassert_true(err == 0, "Entry type 3 wrong value");

	/* Look for non-existing entry */
	offset = 0;
	entry.type = 0;
	while ((entry.type != 5) && (offset < HAYSTACK_BYTES)) {
		zb_step_tlv(test_haystack, &offset, &entry);
	}
	zassert_false(entry.type == 5, "Found non-existing entry");

}

/**
 * @brief Test the opening of a tlv area without signature verification
 */
void test_zb_tlv_open_unsigned(void)
{
	int err, cnt;
	struct zb_slt_area area;
	tlv_area_hdr hdr;
	u8_t ext_haystack[sizeof(tlv_area_hdr) + HAYSTACK_BYTES];
	int ext_haystack_size;
	tlv_entry entry;
	off_t offset;

	hdr.tlva_magic = TLV_AREA_MAGIC;
	hdr.tlva_size = sizeof(ext_haystack);
	memcpy(&hdr.tlva_signature, test_signature, SIGNATURE_BYTES);

	cnt = zb_slt_area_cnt();
	zassert_false(cnt == 0,  "Unable to get slotarea count: [cnt %d]", cnt);

	err = zb_slt_area_get(&area, 0);
	zassert_true(err == 0,  "Unable to get slotarea info: [err %d]", err);

	err = zb_flash_erase(area.slt0_fldev, area.slt0_offset, area.slt0_size);
	zassert_true(err == 0,  "Unable to erase image 0 area: [err %d]", err);

	memcpy(ext_haystack, &hdr, sizeof(tlv_area_hdr));
	memcpy(ext_haystack + sizeof(tlv_area_hdr), test_haystack,
	       sizeof(test_haystack));
	err = zb_flash_write(area.slt0_fldev, area.slt0_offset, ext_haystack,
			     sizeof(ext_haystack));
	zassert_true(err == 0,  "Unable to write tlva: [err %d]", err);

	ext_haystack_size = zb_open_tlv_area(area.slt0_fldev, area.slt0_offset,
					     ext_haystack, false);
	zassert_true(ext_haystack_size >= 0, "Tlv open error");
	zassert_true(ext_haystack_size == HAYSTACK_BYTES, "Tlv length error");

	offset = 0;
	while (offset < HAYSTACK_BYTES) {

		zb_step_tlv(ext_haystack, &offset, &entry);
		switch (entry.type) {
			case 1:
				err = memcmp(&test_haystack[2], entry.value,
					     entry.length);
				zassert_true(err == 0, "type 1 error");
				break;
			case 2:
				err = memcmp(&test_haystack[6], entry.value,
					     entry.length);
				zassert_true(err == 0, "type 2 error");
				break;
			case 3:
				err = memcmp(&test_haystack[11], entry.value,
					     entry.length);
				zassert_true(err == 0, "type 3 error");
				break;
		}

	}
	zassert_true(offset == HAYSTACK_BYTES, "Tlv wrong end [%d]", offset);

}

/**
 * @brief Test the opening of a tlv area with signature verification
 */
void test_zb_tlv_open_signed(void)
{
	int err, cnt;
	struct zb_slt_area area;
	tlv_area_hdr hdr;
	u8_t ext_haystack[sizeof(tlv_area_hdr) + HASH_BYTES];
	int ext_haystack_size;

	hdr.tlva_magic = TLV_AREA_MAGIC;
	hdr.tlva_size = sizeof(ext_haystack);
	memcpy(&hdr.tlva_signature, test_signature, SIGNATURE_BYTES);

	cnt = zb_slt_area_cnt();
	zassert_false(cnt == 0,  "Unable to get slotarea count: [cnt %d]", cnt);

	err = zb_slt_area_get(&area, 0);
	zassert_true(err == 0,  "Unable to get slotarea info: [err %d]", err);

	err = zb_flash_erase(area.slt0_fldev, area.slt0_offset, area.slt0_size);
	zassert_true(err == 0,  "Unable to erase image 0 area: [err %d]", err);

	memcpy(ext_haystack, &hdr, sizeof(tlv_area_hdr));
	memcpy(ext_haystack + sizeof(tlv_area_hdr), test_msg, HASH_BYTES);
	err = zb_flash_write(area.slt0_fldev, area.slt0_offset, ext_haystack,
			     sizeof(ext_haystack));

	ext_haystack_size = zb_open_tlv_area(area.slt0_fldev, area.slt0_offset,
					     ext_haystack, true);
	zassert_true(ext_haystack_size >= 0, "Tlv open error");
	zassert_true(ext_haystack_size == HASH_BYTES,
		     "Incorrect tlv length");

}



void test_zb_tlv(void)
{
	ztest_test_suite(test_zb_tlv,
			 ztest_unit_test(test_zb_tlv_step),
			 ztest_unit_test(test_zb_tlv_open_unsigned),
			 ztest_unit_test(test_zb_tlv_open_signed)
			);

	ztest_run_test_suite(test_zb_tlv);
}
```

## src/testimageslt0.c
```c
const unsigned char test_image_slt0[1536] = {
	0x41, 0x56, 0x4c, 0x54, 0x83, 0x00, 0x00, 0x00,
	0xa5, 0xc8, 0xd3, 0x9c, 0x69, 0x91, 0xae, 0xa5,
	0x88, 0x18, 0x50, 0xb3, 0x3d, 0x18, 0x2f, 0x69,
	0xa8, 0xab, 0x22, 0xd0, 0x0e, 0x6b, 0x5b, 0x9c,
	0xbd, 0x89, 0x6e, 0x6c, 0xfa, 0x01, 0x22, 0x04,
	0x06, 0xdb, 0xda, 0x47, 0x64, 0xd7, 0x04, 0x97,
	0xeb, 0x3c, 0xf1, 0x70, 0x4a, 0xcb, 0x81, 0x3b,
	0x48, 0x95, 0x42, 0xf0, 0x1e, 0xd7, 0xcc, 0xd0,
	0xd1, 0xeb, 0x55, 0x21, 0xf7, 0x2d, 0x04, 0x50,
	0x10, 0x01, 0x00, 0x20, 0x14, 0x00, 0x02, 0x00,
	0x00, 0x00, 0x04, 0x00, 0x00, 0x00, 0x12, 0x01,
	0x00, 0x00, 0x00, 0x00, 0x00, 0x00, 0x00, 0x00,
	0x00, 0x30, 0x20, 0x5f, 0x70, 0xbf, 0x18, 0xa0,
	0x86, 0x00, 0x70, 0x16, 0xe9, 0x48, 0xb0, 0x4a,
	0xed, 0x3b, 0x82, 0x10, 0x3a, 0x36, 0xbe, 0xa4,
	0x17, 0x55, 0xb6, 0xcd, 0xdf, 0xaf, 0x10, 0xac,
	0xe3, 0xc6, 0xef, 0xff, 0xff, 0xff, 0xff, 0xff,
	0xff, 0xff, 0xff, 0xff, 0xff, 0xff, 0xff, 0xff,
	0xff, 0xff, 0xff, 0xff, 0xff, 0xff, 0xff, 0xff,
	0xff, 0xff, 0xff, 0xff, 0xff, 0xff, 0xff, 0xff,
	0xff, 0xff, 0xff, 0xff, 0xff, 0xff, 0xff, 0xff,
	0xff, 0xff, 0xff, 0xff, 0xff, 0xff, 0xff, 0xff,
	0xff, 0xff, 0xff, 0xff, 0xff, 0xff, 0xff, 0xff,
	0xff, 0xff, 0xff, 0xff, 0xff, 0xff, 0xff, 0xff,
	0xff, 0xff, 0xff, 0xff, 0xff, 0xff, 0xff, 0xff,
	0xff, 0xff, 0xff, 0xff, 0xff, 0xff, 0xff, 0xff,
	0xff, 0xff, 0xff, 0xff, 0xff, 0xff, 0xff, 0xff,
	0xff, 0xff, 0xff, 0xff, 0xff, 0xff, 0xff, 0xff,
	0xff, 0xff, 0xff, 0xff, 0xff, 0xff, 0xff, 0xff,
	0xff, 0xff, 0xff, 0xff, 0xff, 0xff, 0xff, 0xff,
	0xff, 0xff, 0xff, 0xff, 0xff, 0xff, 0xff, 0xff,
	0xff, 0xff, 0xff, 0xff, 0xff, 0xff, 0xff, 0xff,
	0xff, 0xff, 0xff, 0xff, 0xff, 0xff, 0xff, 0xff,
	0xff, 0xff, 0xff, 0xff, 0xff, 0xff, 0xff, 0xff,
	0xff, 0xff, 0xff, 0xff, 0xff, 0xff, 0xff, 0xff,
	0xff, 0xff, 0xff, 0xff, 0xff, 0xff, 0xff, 0xff,
	0xff, 0xff, 0xff, 0xff, 0xff, 0xff, 0xff, 0xff,
	0xff, 0xff, 0xff, 0xff, 0xff, 0xff, 0xff, 0xff,
	0xff, 0xff, 0xff, 0xff, 0xff, 0xff, 0xff, 0xff,
	0xff, 0xff, 0xff, 0xff, 0xff, 0xff, 0xff, 0xff,
	0xff, 0xff, 0xff, 0xff, 0xff, 0xff, 0xff, 0xff,
	0xff, 0xff, 0xff, 0xff, 0xff, 0xff, 0xff, 0xff,
	0xff, 0xff, 0xff, 0xff, 0xff, 0xff, 0xff, 0xff,
	0xff, 0xff, 0xff, 0xff, 0xff, 0xff, 0xff, 0xff,
	0xff, 0xff, 0xff, 0xff, 0xff, 0xff, 0xff, 0xff,
	0xff, 0xff, 0xff, 0xff, 0xff, 0xff, 0xff, 0xff,
	0xff, 0xff, 0xff, 0xff, 0xff, 0xff, 0xff, 0xff,
	0xff, 0xff, 0xff, 0xff, 0xff, 0xff, 0xff, 0xff,
	0xff, 0xff, 0xff, 0xff, 0xff, 0xff, 0xff, 0xff,
	0xff, 0xff, 0xff, 0xff, 0xff, 0xff, 0xff, 0xff,
	0xff, 0xff, 0xff, 0xff, 0xff, 0xff, 0xff, 0xff,
	0xff, 0xff, 0xff, 0xff, 0xff, 0xff, 0xff, 0xff,
	0xff, 0xff, 0xff, 0xff, 0xff, 0xff, 0xff, 0xff,
	0xff, 0xff, 0xff, 0xff, 0xff, 0xff, 0xff, 0xff,
	0xff, 0xff, 0xff, 0xff, 0xff, 0xff, 0xff, 0xff,
	0xff, 0xff, 0xff, 0xff, 0xff, 0xff, 0xff, 0xff,
	0xff, 0xff, 0xff, 0xff, 0xff, 0xff, 0xff, 0xff,
	0xff, 0xff, 0xff, 0xff, 0xff, 0xff, 0xff, 0xff,
	0xff, 0xff, 0xff, 0xff, 0xff, 0xff, 0xff, 0xff,
	0xff, 0xff, 0xff, 0xff, 0xff, 0xff, 0xff, 0xff,
	0xff, 0xff, 0xff, 0xff, 0xff, 0xff, 0xff, 0xff,
	0xff, 0xff, 0xff, 0xff, 0xff, 0xff, 0xff, 0xff,
	0xff, 0xff, 0xff, 0xff, 0xff, 0xff, 0xff, 0xff,
	0xff, 0xff, 0xff, 0xff, 0xff, 0xff, 0xff, 0xff,
	0x00, 0x00, 0x00, 0x00, 0x00, 0x00, 0x00, 0x00,
	0x00, 0x00, 0x00, 0x00, 0x00, 0x00, 0x00, 0x00,
	0x00, 0x00, 0x00, 0x00, 0x00, 0x00, 0x00, 0x00,
	0x00, 0x00, 0x00, 0x00, 0x00, 0x00, 0x00, 0x00,
	0x00, 0x00, 0x00, 0x00, 0x00, 0x00, 0x00, 0x00,
	0x00, 0x00, 0x00, 0x00, 0x00, 0x00, 0x00, 0x00,
	0x00, 0x00, 0x00, 0x00, 0x00, 0x00, 0x00, 0x00,
	0x00, 0x00, 0x00, 0x00, 0x00, 0x00, 0x00, 0x00,
	0x00, 0x00, 0x00, 0x00, 0x00, 0x00, 0x00, 0x00,
	0x00, 0x00, 0x00, 0x00, 0x00, 0x00, 0x00, 0x00,
	0x00, 0x00, 0x00, 0x00, 0x00, 0x00, 0x00, 0x00,
	0x00, 0x00, 0x00, 0x00, 0x00, 0x00, 0x00, 0x00,
	0x00, 0x00, 0x00, 0x00, 0x00, 0x00, 0x00, 0x00,
	0x00, 0x00, 0x00, 0x00, 0x00, 0x00, 0x00, 0x00,
	0x00, 0x00, 0x00, 0x00, 0x00, 0x00, 0x00, 0x00,
	0x00, 0x00, 0x00, 0x00, 0x00, 0x00, 0x00, 0x00,
	0x00, 0x00, 0x00, 0x00, 0x00, 0x00, 0x00, 0x00,
	0x00, 0x00, 0x00, 0x00, 0x00, 0x00, 0x00, 0x00,
	0x00, 0x00, 0x00, 0x00, 0x00, 0x00, 0x00, 0x00,
	0x00, 0x00, 0x00, 0x00, 0x00, 0x00, 0x00, 0x00,
	0x00, 0x00, 0x00, 0x00, 0x00, 0x00, 0x00, 0x00,
	0x00, 0x00, 0x00, 0x00, 0x00, 0x00, 0x00, 0x00,
	0x00, 0x00, 0x00, 0x00, 0x00, 0x00, 0x00, 0x00,
	0x00, 0x00, 0x00, 0x00, 0x00, 0x00, 0x00, 0x00,
	0x00, 0x00, 0x00, 0x00, 0x00, 0x00, 0x00, 0x00,
	0x00, 0x00, 0x00, 0x00, 0x00, 0x00, 0x00, 0x00,
	0x00, 0x00, 0x00, 0x00, 0x00, 0x00, 0x00, 0x00,
	0x00, 0x00, 0x00, 0x00, 0x00, 0x00, 0x00, 0x00,
	0x00, 0x00, 0x00, 0x00, 0x00, 0x00, 0x00, 0x00,
	0x00, 0x00, 0x00, 0x00, 0x00, 0x00, 0x00, 0x00,
	0x00, 0x00, 0x00, 0x00, 0x00, 0x00, 0x00, 0x00,
	0x00, 0x00, 0x00, 0x00, 0x00, 0x00, 0x00, 0x00,
	0x00, 0x00, 0x00, 0x00, 0x00, 0x00, 0x00, 0x00,
	0x00, 0x00, 0x00, 0x00, 0x00, 0x00, 0x00, 0x00,
	0x00, 0x00, 0x00, 0x00, 0x00, 0x00, 0x00, 0x00,
	0x00, 0x00, 0x00, 0x00, 0x00, 0x00, 0x00, 0x00,
	0x00, 0x00, 0x00, 0x00, 0x00, 0x00, 0x00, 0x00,
	0x00, 0x00, 0x00, 0x00, 0x00, 0x00, 0x00, 0x00,
	0x00, 0x00, 0x00, 0x00, 0x00, 0x00, 0x00, 0x00,
	0x00, 0x00, 0x00, 0x00, 0x00, 0x00, 0x00, 0x00,
	0x00, 0x00, 0x00, 0x00, 0x00, 0x00, 0x00, 0x00,
	0x00, 0x00, 0x00, 0x00, 0x00, 0x00, 0x00, 0x00,
	0x00, 0x00, 0x00, 0x00, 0x00, 0x00, 0x00, 0x00,
	0x00, 0x00, 0x00, 0x00, 0x00, 0x00, 0x00, 0x00,
	0x00, 0x00, 0x00, 0x00, 0x00, 0x00, 0x00, 0x00,
	0x00, 0x00, 0x00, 0x00, 0x00, 0x00, 0x00, 0x00,
	0x00, 0x00, 0x00, 0x00, 0x00, 0x00, 0x00, 0x00,
	0x00, 0x00, 0x00, 0x00, 0x00, 0x00, 0x00, 0x00,
	0x00, 0x00, 0x00, 0x00, 0x00, 0x00, 0x00, 0x00,
	0x00, 0x00, 0x00, 0x00, 0x00, 0x00, 0x00, 0x00,
	0x00, 0x00, 0x00, 0x00, 0x00, 0x00, 0x00, 0x00,
	0x00, 0x00, 0x00, 0x00, 0x00, 0x00, 0x00, 0x00,
	0x00, 0x00, 0x00, 0x00, 0x00, 0x00, 0x00, 0x00,
	0x00, 0x00, 0x00, 0x00, 0x00, 0x00, 0x00, 0x00,
	0x00, 0x00, 0x00, 0x00, 0x00, 0x00, 0x00, 0x00,
	0x00, 0x00, 0x00, 0x00, 0x00, 0x00, 0x00, 0x00,
	0x00, 0x00, 0x00, 0x00, 0x00, 0x00, 0x00, 0x00,
	0x00, 0x00, 0x00, 0x00, 0x00, 0x00, 0x00, 0x00,
	0x00, 0x00, 0x00, 0x00, 0x00, 0x00, 0x00, 0x00,
	0x00, 0x00, 0x00, 0x00, 0x00, 0x00, 0x00, 0x00,
	0x00, 0x00, 0x00, 0x00, 0x00, 0x00, 0x00, 0x00,
	0x00, 0x00, 0x00, 0x00, 0x00, 0x00, 0x00, 0x00,
	0x00, 0x00, 0x00, 0x00, 0x00, 0x00, 0x00, 0x00,
	0x00, 0x00, 0x00, 0x00, 0x00, 0x00, 0x00, 0x00,
	0x00, 0x00, 0x00, 0x00, 0x00, 0x00, 0x00, 0x00,
	0x00, 0x00, 0x00, 0x00, 0x00, 0x00, 0x00, 0x00,
	0x00, 0x00, 0x00, 0x00, 0x00, 0x00, 0x00, 0x00,
	0x00, 0x00, 0x00, 0x00, 0x00, 0x00, 0x00, 0x00,
	0x00, 0x00, 0x00, 0x00, 0x00, 0x00, 0x00, 0x00,
	0x00, 0x00, 0x00, 0x00, 0x00, 0x00, 0x00, 0x00,
	0x00, 0x00, 0x00, 0x00, 0x00, 0x00, 0x00, 0x00,
	0x00, 0x00, 0x00, 0x00, 0x00, 0x00, 0x00, 0x00,
	0x00, 0x00, 0x00, 0x00, 0x00, 0x00, 0x00, 0x00,
	0x00, 0x00, 0x00, 0x00, 0x00, 0x00, 0x00, 0x00,
	0x00, 0x00, 0x00, 0x00, 0x00, 0x00, 0x00, 0x00,
	0x00, 0x00, 0x00, 0x00, 0x00, 0x00, 0x00, 0x00,
	0x00, 0x00, 0x00, 0x00, 0x00, 0x00, 0x00, 0x00,
	0x00, 0x00, 0x00, 0x00, 0x00, 0x00, 0x00, 0x00,
	0x00, 0x00, 0x00, 0x00, 0x00, 0x00, 0x00, 0x00,
	0x00, 0x00, 0x00, 0x00, 0x00, 0x00, 0x00, 0x00,
	0x00, 0x00, 0x00, 0x00, 0x00, 0x00, 0x00, 0x00,
	0x00, 0x00, 0x00, 0x00, 0x00, 0x00, 0x00, 0x00,
	0x00, 0x00, 0x00, 0x00, 0x00, 0x00, 0x00, 0x00,
	0x00, 0x00, 0x00, 0x00, 0x00, 0x00, 0x00, 0x00,
	0x00, 0x00, 0x00, 0x00, 0x00, 0x00, 0x00, 0x00,
	0x00, 0x00, 0x00, 0x00, 0x00, 0x00, 0x00, 0x00,
	0x00, 0x00, 0x00, 0x00, 0x00, 0x00, 0x00, 0x00,
	0x00, 0x00, 0x00, 0x00, 0x00, 0x00, 0x00, 0x00,
	0x00, 0x00, 0x00, 0x00, 0x00, 0x00, 0x00, 0x00,
	0x00, 0x00, 0x00, 0x00, 0x00, 0x00, 0x00, 0x00,
	0x00, 0x00, 0x00, 0x00, 0x00, 0x00, 0x00, 0x00,
	0x00, 0x00, 0x00, 0x00, 0x00, 0x00, 0x00, 0x00,
	0x00, 0x00, 0x00, 0x00, 0x00, 0x00, 0x00, 0x00,
	0x00, 0x00, 0x00, 0x00, 0x00, 0x00, 0x00, 0x00,
	0x00, 0x00, 0x00, 0x00, 0x00, 0x00, 0x00, 0x00,
	0x00, 0x00, 0x00, 0x00, 0x00, 0x00, 0x00, 0x00,
	0x00, 0x00, 0x00, 0x00, 0x00, 0x00, 0x00, 0x00,
	0x00, 0x00, 0x00, 0x00, 0x00, 0x00, 0x00, 0x00,
	0x00, 0x00, 0x00, 0x00, 0x00, 0x00, 0x00, 0x00,
	0x00, 0x00, 0x00, 0x00, 0x00, 0x00, 0x00, 0x00,
	0x00, 0x00, 0x00, 0x00, 0x00, 0x00, 0x00, 0x00,
	0x00, 0x00, 0x00, 0x00, 0x00, 0x00, 0x00, 0x00,
	0x00, 0x00, 0x00, 0x00, 0x00, 0x00, 0x00, 0x00,
	0x00, 0x00, 0x00, 0x00, 0x00, 0x00, 0x00, 0x00,
	0x00, 0x00, 0x00, 0x00, 0x00, 0x00, 0x00, 0x00,
	0x00, 0x00, 0x00, 0x00, 0x00, 0x00, 0x00, 0x00,
	0x00, 0x00, 0x00, 0x00, 0x00, 0x00, 0x00, 0x00,
	0x00, 0x00, 0x00, 0x00, 0x00, 0x00, 0x00, 0x00,
	0x00, 0x00, 0x00, 0x00, 0x00, 0x00, 0x00, 0x00,
	0x00, 0x00, 0x00, 0x00, 0x00, 0x00, 0x00, 0x00,
	0x00, 0x00, 0x00, 0x00, 0x00, 0x00, 0x00, 0x00,
	0x00, 0x00, 0x00, 0x00, 0x00, 0x00, 0x00, 0x00,
	0x00, 0x00, 0x00, 0x00, 0x00, 0x00, 0x00, 0x00,
	0x00, 0x00, 0x00, 0x00, 0x00, 0x00, 0x00, 0x00,
	0x00, 0x00, 0x00, 0x00, 0x00, 0x00, 0x00, 0x00,
	0x00, 0x00, 0x00, 0x00, 0x00, 0x00, 0x00, 0x00,
	0x00, 0x00, 0x00, 0x00, 0x00, 0x00, 0x00, 0x00,
	0x00, 0x00, 0x00, 0x00, 0x00, 0x00, 0x00, 0x00,
	0x00, 0x00, 0x00, 0x00, 0x00, 0x00, 0x00, 0x00,
	0x00, 0x00, 0x00, 0x00, 0x00, 0x00, 0x00, 0x00,
	0x00, 0x00, 0x00, 0x00, 0x00, 0x00, 0x00, 0x00,
	0x00, 0x00, 0x00, 0x00, 0x00, 0x00, 0x00, 0x00,
	0x00, 0x00, 0x00, 0x00, 0x00, 0x00, 0x00, 0x00,
	0x00, 0x00, 0x00, 0x00, 0x00, 0x00, 0x00, 0x00,
	0x00, 0x00, 0x00, 0x00, 0x00, 0x00, 0x00, 0x00,
	0x00, 0x00, 0x00, 0x00, 0x00, 0x00, 0x00, 0x00,
	0x00, 0x00, 0x00, 0x00, 0x00, 0x00, 0x00, 0x00,
	0x00, 0x00, 0x00, 0x00, 0x00, 0x00, 0x00, 0x00,
};
```

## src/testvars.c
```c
/*
 * Copyright (c) 2018 Laczen: Set of keys to test signing and encryption
 * key exchange.
 *
 * Keys definition: the bootloader has two types of keys:
 * a. A private encryption key that is used to derive the encryption key
 * b. A set of root public keys that is used to validate images
 *
 * SPDX-License-Identifier: Apache-2.0
 */
#include <zephyr.h>
#include "../../zepboot/include/zb_ec256.h"

u8_t test_msg[HASH_BYTES] = {
	0xff, 0xfe, 0xfd, 0xfc, 0xfb, 0xfa, 0xf9, 0xf8,
	0xf7, 0xf6, 0xf5, 0xf4, 0xf3, 0xf2, 0xf1, 0xf0,
	0xff, 0xfe, 0xfd, 0xfc, 0xfb, 0xfa, 0xf9, 0xf8,
	0xf7, 0xf6, 0xf5, 0xf4, 0xf3, 0xf2, 0xf1, 0xf0
};


u8_t test_msg_hash[HASH_BYTES] = {
	87, 43, 26, 198, 187, 148, 71, 79,
	220, 38, 223, 89, 4, 118, 115, 109,
	231, 185, 12, 231, 123, 212, 221, 103,
	117, 243, 241, 37, 134, 175, 136, 251
};

u32_t test_msg_crc32 = 0x4D299FC3;

u8_t test_signature[SIGNATURE_BYTES] = {
	252, 86, 17, 53, 85, 142, 204, 211,
	55, 184, 117, 91, 159, 134, 6, 189,
	152, 48, 212, 168, 153, 194, 37, 69,
	159, 214, 44, 58, 39, 64, 19, 36,
	175, 12, 24, 179, 83, 243, 204, 68,
	125, 110, 101, 58, 175, 226, 88, 44,
	44, 100, 215, 166, 176, 109, 107, 238,
	238, 129, 253, 12, 66, 182, 43, 27
};

u8_t test_enc_pub_key[PUBLIC_KEY_BYTES] = {
	162, 232, 188, 223, 146, 244, 15, 182,
	171, 144, 101, 158, 237, 57, 205, 66,
	164, 144, 209, 239, 44, 138, 85, 163,
	97, 222, 197, 80, 96, 83, 34, 117,
	201, 36, 44, 25, 158, 7, 5, 165,
	73, 27, 116, 124, 239, 11, 239, 8,
	54, 48, 235, 178, 121, 206, 207, 21,
	192, 36, 184, 152, 219, 62, 106, 175
};

u8_t test_enc_key[16] = {
	100, 94, 130, 145, 92, 49, 78, 162,
	75, 150, 19, 98, 20, 112, 197, 170
};
```

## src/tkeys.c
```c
/*
 * Copyright (c) 2018 Laczen
 *
 * Keys definition: the bootloader has two types of keys:
 * a. A private encryption key that is used to derive the encryption key
 * b. A set of root public keys that is used to validate images
 *
 * SPDX-License-Identifier: Apache-2.0
 */


const unsigned char ec256_boot_pri_key[] = {
	0xf6, 0x96, 0xe9, 0x4f, 0xa5, 0x5d, 0xd1, 0xda,
	0x2b, 0x77, 0x44, 0x8d, 0x5b, 0x0a, 0x25, 0x3d,
	0x6b, 0x12, 0x59, 0xe9, 0x7f, 0x9f, 0x75, 0x18,
	0x9c, 0xa3, 0xbd, 0x2c, 0x3a, 0x17, 0x5d, 0x83,
};

const unsigned int ec256_boot_pri_key_len = 32;

const unsigned char ec256_root_pub_key[] = {
	/* First part is a bad key */
	0x1e, 0x8d, 0xef, 0xb8, 0x12, 0xf7, 0x2d, 0x71,
	0x2f, 0xdf, 0xc5, 0xa5, 0x2c, 0x08, 0x5d, 0xc8,
	0xd5, 0x7d, 0x8f, 0x5b, 0xa9, 0xa4, 0x93, 0xf3,
	0xe7, 0x9e, 0x37, 0x98, 0xef, 0xf8, 0xbd, 0x41,
	0x37, 0x94, 0x32, 0x79, 0xea, 0x3b, 0xdc, 0xd4,
	0x9a, 0xc9, 0xb0, 0x98, 0x06, 0x33, 0xee, 0x83,
	0xfd, 0x24, 0x81, 0xfe, 0x09, 0xfa, 0xd3, 0xde,
	0xda, 0xc0, 0x13, 0xd0, 0xad, 0x2b, 0x15, 0x1d,
	/* This is a good key for test_image
	 * but bad for test signature */
	0x2e, 0x8d, 0xef, 0xb8, 0x12, 0xf7, 0x2d, 0x71,
	0x2f, 0xdf, 0xc5, 0xa5, 0x2c, 0x08, 0x5d, 0xc8,
	0xd5, 0x7d, 0x8f, 0x5b, 0xa9, 0xa4, 0x93, 0xf3,
	0xe7, 0x9e, 0x37, 0x98, 0xef, 0xf8, 0xbd, 0x41,
	0x37, 0x94, 0x32, 0x79, 0xea, 0x3b, 0xdc, 0xd4,
	0x9a, 0xc9, 0xb0, 0x98, 0x06, 0x33, 0xee, 0x83,
	0xfd, 0x24, 0x81, 0xfe, 0x09, 0xfa, 0xd3, 0xde,
	0xda, 0xc0, 0x13, 0xd0, 0xad, 0x2b, 0x15, 0x1d,
	/* This is a good key and test_signature
	 * but bad for test_image */
	0xac, 0x4b, 0xea, 0x21, 0xbf, 0xb6, 0x2f, 0xfc,
	0x1b, 0x89, 0xb6, 0xd5, 0x98, 0x67, 0xcd, 0x56,
	0x78, 0x28, 0x22, 0x55, 0xff, 0x39, 0xc2, 0xbb,
	0x93, 0xf8, 0xd1, 0x0b, 0x19, 0xf0, 0x81, 0x88,
	0x72, 0x82, 0x94, 0x22, 0xff, 0x66, 0x67, 0xa7,
	0xf3, 0xe9, 0x28, 0x60, 0x54, 0x96, 0x66, 0xa1,
	0xea, 0xb8, 0xb2, 0x9e, 0x5c, 0x66, 0xc4, 0x02,
	0x90, 0xd9, 0x95, 0xad, 0x97, 0x77, 0x02, 0x2f
};

const unsigned int ec256_root_pub_key_len = 192;
```
